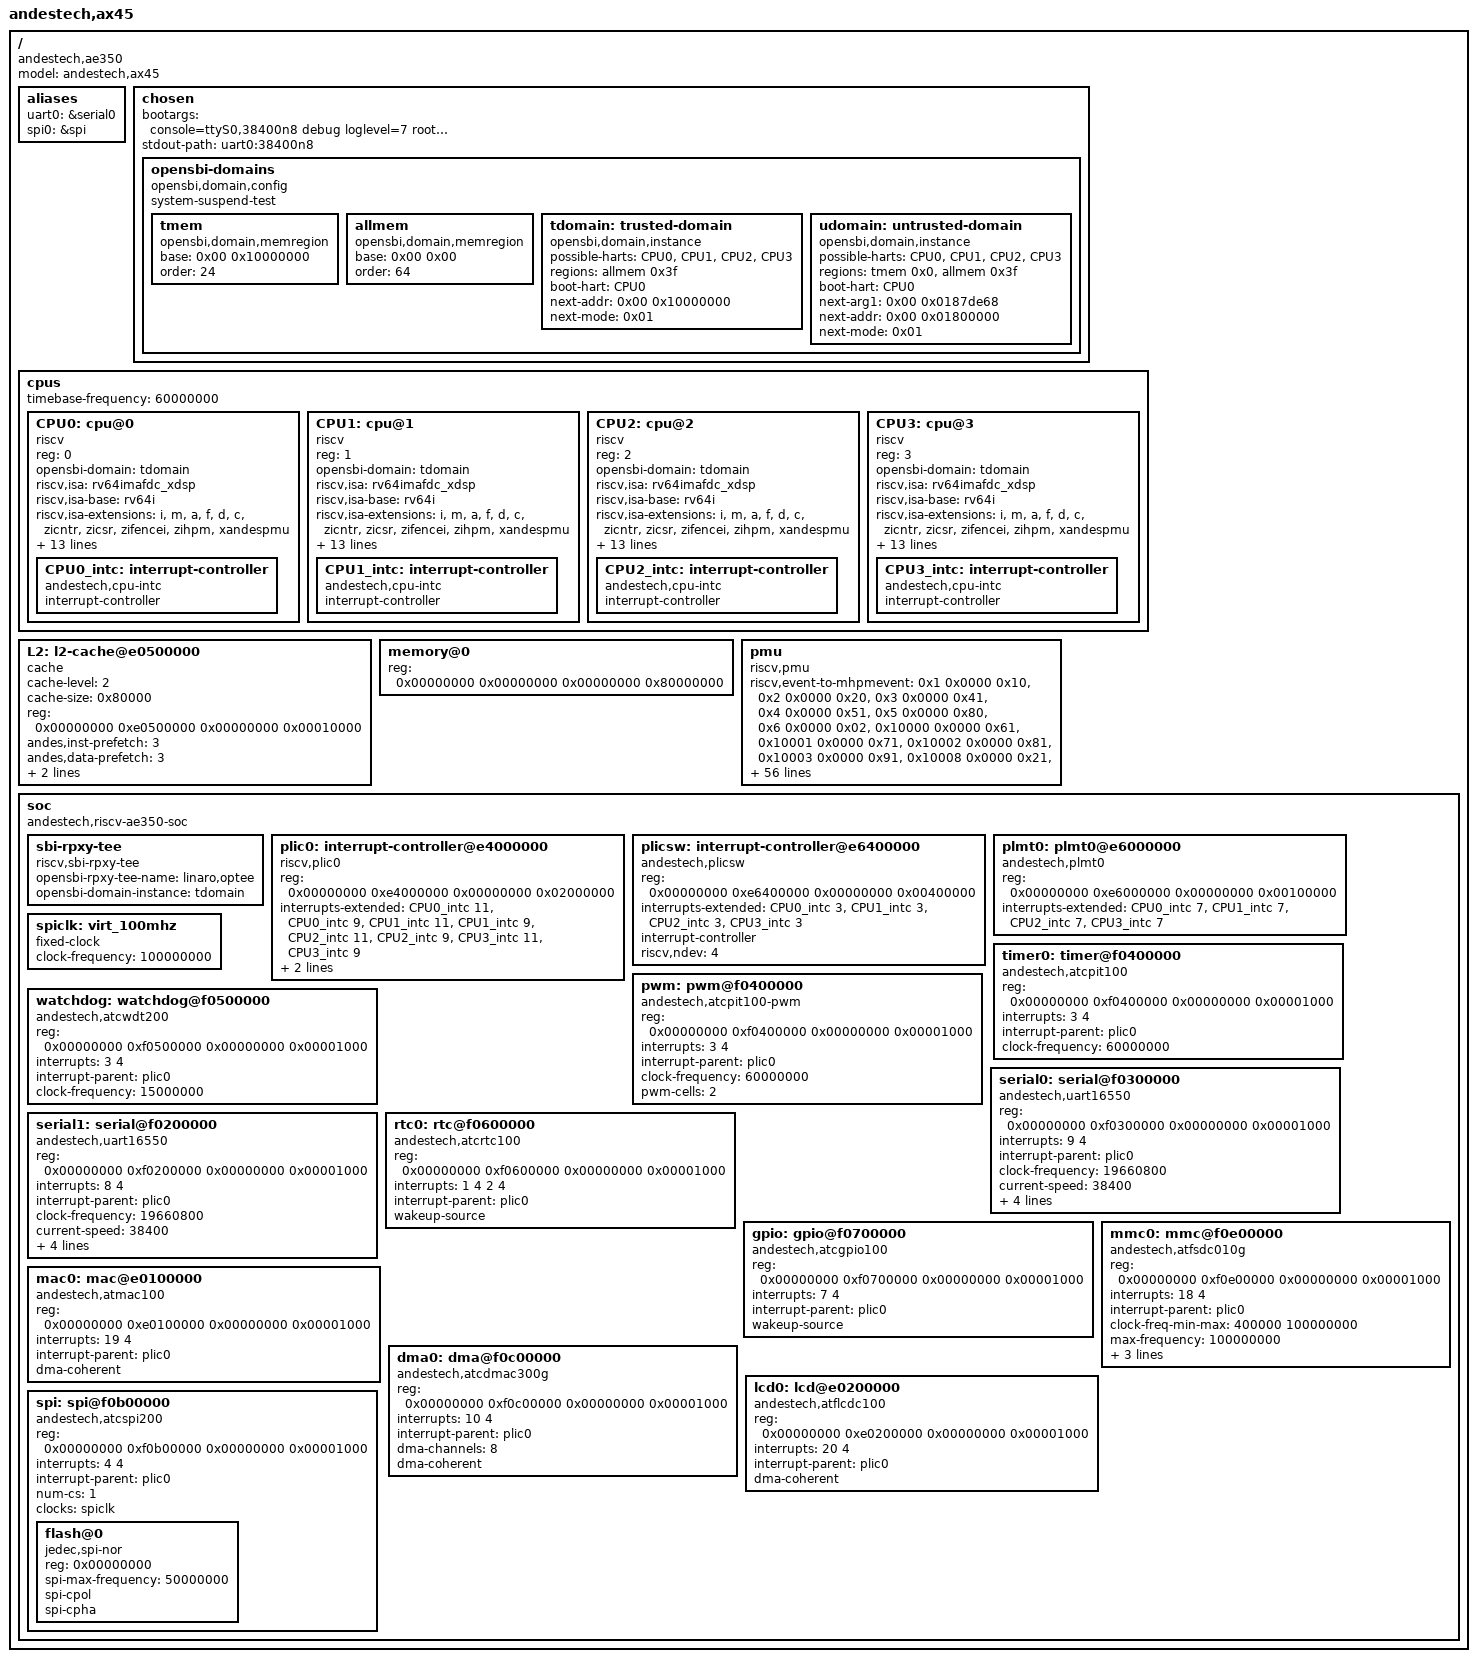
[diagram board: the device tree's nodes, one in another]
/dts-v1/;
/ {
	#address-cells = <2>;
	#size-cells = <2>;
	compatible = "andestech,ae350";
	model = "andestech,ax45";
	aliases {
		uart0 = &serial0;
		spi0 = &spi;
	};
	chosen {
		//bootargs = "earlycon=sbi console=ttyS0,38400n8 debug loglevel=7 rootwait root=/dev/mmcblk0p2 rw";
		bootargs = "console=ttyS0,38400n8 debug loglevel=7 rootwait root=/dev/mmcblk0p2 rw";
		stdout-path = "uart0:38400n8";
		opensbi-domains {
			compatible = "opensbi,domain,config";
			system-suspend-test;

			tmem: tmem {
				compatible = "opensbi,domain,memregion";
				base = <0x00 0x10000000>;
				order = <24>;
			};

			allmem: allmem {
				compatible = "opensbi,domain,memregion";
				base = <0x00 0x00>;
				order = <64>;
			};

			tdomain: trusted-domain {
				compatible = "opensbi,domain,instance";
				possible-harts = <&CPU0 &CPU1 &CPU2 &CPU3>;
				//   (E|SUX|SUW| SUR|MX|MW|MR)
				regions = <&allmem 0x3f>;
				boot-hart = <&CPU0>;
				//next-arg1 = <0x00 0x0187de58>; // dtb : FW_JUMP   : 0x02200000,
							       //       FW_DYNAMIC: use $a1 given by SPL
				next-addr = <0x00 0x10000000>; // tee.bin
				next-mode = <0x01>;
			};

			udomain: untrusted-domain {
				compatible = "opensbi,domain,instance";
				possible-harts = <&CPU0 &CPU1 &CPU2 &CPU3>;
				//   (E|SUX|SUW| SUR|MX|MW|MR)
				regions = <&tmem 0x0 &allmem 0x3f>;
				boot-hart = <&CPU0>;
				next-arg1 = <0x00 0x0187de68>; // dtb : FW_JUMP   : 0x2200000,
							       //       FW_DYNAMIC: 0x0187de58
				next-addr = <0x00 0x01800000>; // u-boot
				next-mode = <0x01>;
			};
		};
	};
	cpus {
		#address-cells = <1>;
		#size-cells = <0>;
		timebase-frequency = <60000000>;
		CPU0: cpu@0 {
			device_type = "cpu";
			reg = <0>;
			status = "okay";
			compatible = "riscv";
			opensbi-domain = <&tdomain>;
			riscv,isa = "rv64imafdc_xdsp";
			riscv,isa-base = "rv64i";
			riscv,isa-extensions = "i", "m", "a", "f", "d", "c", "zicntr", "zicsr",
					       "zifencei", "zihpm", "xandespmu";
			riscv,priv-major = <1>;
			riscv,priv-minor = <10>;
			mmu-type = "riscv,sv48";
			clock-frequency = <60000000>;
			i-cache-size = <0x8000>;
			i-cache-sets = <256>;
			i-cache-line-size = <64>;
			i-cache-block-size = <64>;
			d-cache-size = <0x8000>;
			d-cache-sets = <128>;
			d-cache-line-size = <64>;
			d-cache-block-size = <64>;
			next-level-cache = <&L2>;
			CPU0_intc: interrupt-controller {
				#interrupt-cells = <1>;
				interrupt-controller;
				compatible = "andestech,cpu-intc", "riscv,cpu-intc";
			};
		};
		CPU1: cpu@1 {
			device_type = "cpu";
			reg = <1>;
			status = "okay";
			compatible = "riscv";
			opensbi-domain = <&tdomain>;
			riscv,isa = "rv64imafdc_xdsp";
			riscv,isa-base = "rv64i";
			riscv,isa-extensions = "i", "m", "a", "f", "d", "c", "zicntr", "zicsr",
					       "zifencei", "zihpm", "xandespmu";
			riscv,priv-major = <1>;
			riscv,priv-minor = <10>;
			mmu-type = "riscv,sv48";
			clock-frequency = <60000000>;
			i-cache-size = <0x8000>;
			i-cache-sets = <256>;
			i-cache-line-size = <64>;
			i-cache-block-size = <64>;
			d-cache-size = <0x8000>;
			d-cache-sets = <128>;
			d-cache-line-size = <64>;
			d-cache-block-size = <64>;
			next-level-cache = <&L2>;
			CPU1_intc: interrupt-controller {
				#interrupt-cells = <1>;
				interrupt-controller;
				compatible = "andestech,cpu-intc", "riscv,cpu-intc";
			};
		};
		CPU2: cpu@2 {
			device_type = "cpu";
			reg = <2>;
			status = "okay";
			compatible = "riscv";
			opensbi-domain = <&tdomain>;
			riscv,isa = "rv64imafdc_xdsp";
			riscv,isa-base = "rv64i";
			riscv,isa-extensions = "i", "m", "a", "f", "d", "c", "zicntr", "zicsr",
					       "zifencei", "zihpm", "xandespmu";
			riscv,priv-major = <1>;
			riscv,priv-minor = <10>;
			mmu-type = "riscv,sv48";
			clock-frequency = <60000000>;
			i-cache-size = <0x8000>;
			i-cache-sets = <256>;
			i-cache-line-size = <64>;
			i-cache-block-size = <64>;
			d-cache-size = <0x8000>;
			d-cache-sets = <128>;
			d-cache-line-size = <64>;
			d-cache-block-size = <64>;
			next-level-cache = <&L2>;
			CPU2_intc: interrupt-controller {
				#interrupt-cells = <1>;
				interrupt-controller;
				compatible = "andestech,cpu-intc", "riscv,cpu-intc";
			};
		};
		CPU3: cpu@3 {
			device_type = "cpu";
			reg = <3>;
			status = "okay";
			compatible = "riscv";
			opensbi-domain = <&tdomain>;
			riscv,isa = "rv64imafdc_xdsp";
			riscv,isa-base = "rv64i";
			riscv,isa-extensions = "i", "m", "a", "f", "d", "c", "zicntr", "zicsr",
					       "zifencei", "zihpm", "xandespmu";
			riscv,priv-major = <1>;
			riscv,priv-minor = <10>;
			mmu-type = "riscv,sv48";
			clock-frequency = <60000000>;
			i-cache-size = <0x8000>;
			i-cache-sets = <256>;
			i-cache-line-size = <64>;
			i-cache-block-size = <64>;
			d-cache-size = <0x8000>;
			d-cache-sets = <128>;
			d-cache-line-size = <64>;
			d-cache-block-size = <64>;
			next-level-cache = <&L2>;
			CPU3_intc: interrupt-controller {
				#interrupt-cells = <1>;
				interrupt-controller;
				compatible = "andestech,cpu-intc", "riscv,cpu-intc";
			};
		};
	};
	L2: l2-cache@e0500000 {
		compatible = "cache";
		cache-level = <2>;
		cache-size = <0x80000>;
		reg = <0x00000000 0xe0500000 0x00000000 0x00010000>;
		andes,inst-prefetch = <3>;
		andes,data-prefetch = <3>;
		// The value format is <XRAMOCTL XRAMICTL>
		andes,tag-ram-ctl = <1 0>;
		andes,data-ram-ctl = <1 0>;
	};

	memory@0 {
		reg = <0x00000000 0x00000000 0x00000000 0x80000000>;
		device_type = "memory";
	};
	pmu: pmu {
		compatible 			= "riscv,pmu";
		riscv,event-to-mhpmevent =
						 <0x1 0x0000 0x10>, /* CPU_CYCLES          -> Cycle count */
						 <0x2 0x0000 0x20>, /* INSTRUCTIONS        -> Retired instruction count */
						 <0x3 0x0000 0x41>, /* CACHE_REFERENCES    -> D-Cache access */
						 <0x4 0x0000 0x51>, /* CACHE_MISSES        -> D-Cache miss */
						 <0x5 0x0000 0x80>, /* BRANCH_INSTRUCTIONS -> Conditional branch instruction count */
						 <0x6 0x0000 0x02>, /* BRANCH_MISSES       -> Misprediction of conditional branches */
						 <0x10000 0x0000 0x61>,  /* L1D_READ_ACCESS  -> D-Cache load access */
						 <0x10001 0x0000 0x71>,  /* L1D_READ_MISS    -> D-Cache load miss */
						 <0x10002 0x0000 0x81>,  /* L1D_WRITE_ACCESS -> D-Cache store access */
						 <0x10003 0x0000 0x91>,  /* L1D_WRITE_MISS   -> D-Cache store miss */
						 <0x10008 0x0000 0x21>,  /* L1I_READ_ACCESS  -> I-Cache access */
						 <0x10009 0x0000 0x31>;  /* L1I_READ_MISS    -> I-Cache miss */
		riscv,event-to-mhpmcounters = <0x1 0x6 0x78>,
					      <0x10000 0x10003 0x78>,
					      <0x10008 0x10009 0x78>;
		riscv,raw-event-to-mhpmcounters =
							<0x0 0x10 0xffffffff 0xffffffff 0x78>, /* Cycle count */
							<0x0 0x20 0xffffffff 0xffffffff 0x78>, /* Retired instruction count */
							<0x0 0x30 0xffffffff 0xffffffff 0x78>, /* Integer load instruction count */
							<0x0 0x40 0xffffffff 0xffffffff 0x78>, /* Integer store instruction count */
							<0x0 0x50 0xffffffff 0xffffffff 0x78>, /* Atomic instruction count */
							<0x0 0x60 0xffffffff 0xffffffff 0x78>, /* System instruction count */
							<0x0 0x70 0xffffffff 0xffffffff 0x78>, /* Integer computational instruction count */
							<0x0 0x80 0xffffffff 0xffffffff 0x78>, /* Conditional branch instruction count */
							<0x0 0x90 0xffffffff 0xffffffff 0x78>, /* Taken conditional branch instruction count */
							<0x0 0xA0 0xffffffff 0xffffffff 0x78>, /* JAL instruction count */
							<0x0 0xB0 0xffffffff 0xffffffff 0x78>, /* JALR instruction count */
							<0x0 0xC0 0xffffffff 0xffffffff 0x78>, /* Return instruction count */
							<0x0 0xD0 0xffffffff 0xffffffff 0x78>, /* Control transfer instruction count */
							<0x0 0xE0 0xffffffff 0xffffffff 0x78>, /* EXEC.IT instruction count */
							<0x0 0xF0 0xffffffff 0xffffffff 0x78>, /* Integer multiplication instruction count */
							<0x0 0x100 0xffffffff 0xffffffff 0x78>, /* Integer division instruction count */
							<0x0 0x110 0xffffffff 0xffffffff 0x78>, /* Floating-point load instruction count */
							<0x0 0x120 0xffffffff 0xffffffff 0x78>, /* Floating-point store instruction count */
							<0x0 0x130 0xffffffff 0xffffffff 0x78>, /* Floating-point addition/subtraction instruction count */
							<0x0 0x140 0xffffffff 0xffffffff 0x78>, /* Floating-point multiplication instruction count */
							<0x0 0x150 0xffffffff 0xffffffff 0x78>, /* Floating-point fused multiply-add instruction count */
							<0x0 0x160 0xffffffff 0xffffffff 0x78>, /* Floating-point division or square-root instruction count */
							<0x0 0x170 0xffffffff 0xffffffff 0x78>, /* Other floating-point instruction count */
							<0x0 0x180 0xffffffff 0xffffffff 0x78>, /* Integer multiplication and add/sub instruction count */
							<0x0 0x190 0xffffffff 0xffffffff 0x78>, /* Retired operation count */
							<0x0 0x01 0xffffffff 0xffffffff 0x78>, /* ILM access */
							<0x0 0x11 0xffffffff 0xffffffff 0x78>, /* DLM access */
							<0x0 0x21 0xffffffff 0xffffffff 0x78>, /* I-Cache access */
							<0x0 0x31 0xffffffff 0xffffffff 0x78>, /* I-Cache miss */
							<0x0 0x41 0xffffffff 0xffffffff 0x78>, /* D-Cache access */
							<0x0 0x51 0xffffffff 0xffffffff 0x78>, /* D-Cache miss */
							<0x0 0x61 0xffffffff 0xffffffff 0x78>, /* D-Cache load access */
							<0x0 0x71 0xffffffff 0xffffffff 0x78>, /* D-Cache load miss */
							<0x0 0x81 0xffffffff 0xffffffff 0x78>, /* D-Cache store access */
							<0x0 0x91 0xffffffff 0xffffffff 0x78>, /* D-Cache store miss */
							<0x0 0xA1 0xffffffff 0xffffffff 0x78>, /* D-Cache writeback */
							<0x0 0xB1 0xffffffff 0xffffffff 0x78>, /* Cycles waiting for I-Cache fill data */
							<0x0 0xC1 0xffffffff 0xffffffff 0x78>, /* Cycles waiting for D-Cache fill data */
							<0x0 0xD1 0xffffffff 0xffffffff 0x78>, /* Uncached fetch data access from bus */
							<0x0 0xE1 0xffffffff 0xffffffff 0x78>, /* Uncached load data access from bus */
							<0x0 0xF1 0xffffffff 0xffffffff 0x78>, /* Cycles waiting for uncached fetch data from bus */
							<0x0 0x101 0xffffffff 0xffffffff 0x78>, /* Cycles waiting for uncached load data from bus */
							<0x0 0x111 0xffffffff 0xffffffff 0x78>, /* Main ITLB access */
							<0x0 0x121 0xffffffff 0xffffffff 0x78>, /* Main ITLB miss */
							<0x0 0x131 0xffffffff 0xffffffff 0x78>, /* Main DTLB access */
							<0x0 0x141 0xffffffff 0xffffffff 0x78>, /* Main DTLB miss */
							<0x0 0x151 0xffffffff 0xffffffff 0x78>, /* Cycles waiting for Main ITLB fill data */
							<0x0 0x161 0xffffffff 0xffffffff 0x78>, /* Pipeline stall cycles caused by Main DTLB miss */
							<0x0 0x171 0xffffffff 0xffffffff 0x78>, /* Hardware prefetch bus access */
							<0x0 0x02 0xffffffff 0xffffffff 0x78>, /* Misprediction of conditional branches */
							<0x0 0x12 0xffffffff 0xffffffff 0x78>, /* Misprediction of taken conditional branches */
							<0x0 0x22 0xffffffff 0xffffffff 0x78>; /* Misprediction of targets of Return instructions */
	};
	soc {
		#address-cells = <2>;
		#size-cells = <2>;
		compatible = "andestech,riscv-ae350-soc", "simple-bus";
		ranges;
		sbi-rpxy-tee {
			opensbi-rpxy-tee-name = "linaro,optee";
			opensbi-domain-instance = <&tdomain>;
			compatible = "riscv,sbi-rpxy-tee";
		};
		plic0: interrupt-controller@e4000000 {
			compatible = "riscv,plic0";
			reg = <0x00000000 0xe4000000 0x00000000 0x02000000>;
			interrupts-extended = < &CPU0_intc 11 &CPU0_intc 9 &CPU1_intc 11 &CPU1_intc 9
						&CPU2_intc 11 &CPU2_intc 9 &CPU3_intc 11 &CPU3_intc 9>;
			interrupt-controller;
			#address-cells = <2>;
			#interrupt-cells = <2>;
			riscv,ndev = <71>;
		};
		plicsw: interrupt-controller@e6400000 {
			compatible = "andestech,plicsw";
			reg = <0x00000000 0xe6400000 0x00000000 0x00400000>;
			interrupts-extended = < &CPU0_intc 3 &CPU1_intc 3
						&CPU2_intc 3 &CPU3_intc 3>;
			interrupt-controller;
			#address-cells = <2>;
			#interrupt-cells = <2>;
			riscv,ndev = <4>;
		};
		plmt0: plmt0@e6000000 {
			compatible = "andestech,plmt0";
			reg = <0x00000000 0xe6000000 0x00000000 0x00100000>;
			interrupts-extended = < &CPU0_intc 7 &CPU1_intc 7
						&CPU2_intc 7 &CPU3_intc 7>;
		};
		spiclk: virt_100mhz {
			compatible = "fixed-clock";
			#clock-cells = <0>;
			clock-frequency = <100000000>;
		};
		timer0: timer@f0400000 {
			compatible = "andestech,atcpit100";
			reg = <0x00000000 0xf0400000 0x00000000 0x00001000>;
			interrupts = <3 4>;
			interrupt-parent = <&plic0>;
			clock-frequency = <60000000>;
		};
		pwm: pwm@f0400000 {
			compatible = "andestech,atcpit100-pwm";
			reg = <0x00000000 0xf0400000 0x00000000 0x00001000>;
			interrupts = <3 4>;
			interrupt-parent = <&plic0>;
			clock-frequency = <60000000>;
			pwm-cells = <2>;
		};
		watchdog: watchdog@f0500000 {
			compatible = "andestech,atcwdt200";
			reg = <0x00000000 0xf0500000 0x00000000 0x00001000>;
			interrupts = <3 4>;
			interrupt-parent = <&plic0>;
			clock-frequency = <15000000>;
		};
		serial0: serial@f0300000 {
			compatible = "andestech,uart16550", "ns16550a";
			reg = <0x00000000 0xf0300000 0x00000000 0x00001000>;
			interrupts = <9 4>;
			interrupt-parent = <&plic0>;
			clock-frequency = <19660800>;
			current-speed = <38400>;
			reg-shift = <2>;
			reg-offset = <32>;
			reg-io-width = <4>;
			no-loopback-test;
		};
serial1: serial@f0200000 {
	compatible = "andestech,uart16550", "ns16550a";
	reg = <0x00000000 0xf0200000 0x00000000 0x00001000>;
	interrupts = <8 4>;
	interrupt-parent = <&plic0>;
	clock-frequency = <19660800>;
	current-speed = <38400>;
	reg-shift = <2>;
	reg-offset = <32>;
	reg-io-width = <4>;
	no-loopback-test;
};
		rtc0: rtc@f0600000 {
			compatible = "andestech,atcrtc100";
			reg = <0x00000000 0xf0600000 0x00000000 0x00001000>;
			interrupts = <1 4 2 4>;
			interrupt-parent = <&plic0>;
			wakeup-source;
		};
		gpio: gpio@f0700000 {
			compatible = "andestech,atcgpio100";
			reg = <0x00000000 0xf0700000 0x00000000 0x00001000>;
			interrupts = <7 4>;
			interrupt-parent = <&plic0>;
			wakeup-source;
		};
		mac0: mac@e0100000 {
			compatible = "andestech,atmac100";
			reg = <0x00000000 0xe0100000 0x00000000 0x00001000>;
			interrupts = <19 4>;
			interrupt-parent = <&plic0>;
		dma-coherent;
		};
		mmc0: mmc@f0e00000 {
			compatible = "andestech,atfsdc010g";
			reg = <0x00000000 0xf0e00000 0x00000000 0x00001000>;
			interrupts = <18 4>;
			interrupt-parent = <&plic0>;
			clock-freq-min-max = <400000 100000000>;
			max-frequency = <100000000>;
			fifo-depth = <16>;
			dmas = <&dma0 9>;
			dma-names = "rxtx";
		dma-coherent;
		};
		dma0: dma@f0c00000 {
			compatible = "andestech,atcdmac300g";
			reg = <0x00000000 0xf0c00000 0x00000000 0x00001000>;
			interrupts = <10 4>;
			interrupt-parent = <&plic0>;
			dma-channels = <8>;
			#dma-cells = <1>;
			dma-coherent;
		};
		lcd0: lcd@e0200000 {
			compatible = "andestech,atflcdc100";
			reg = <0x00000000 0xe0200000 0x00000000 0x00001000>;
			interrupts = <20 4>;
			interrupt-parent = <&plic0>;
		dma-coherent;
		};
		spi: spi@f0b00000 {
			compatible = "andestech,atcspi200";
			reg = <0x00000000 0xf0b00000 0x00000000 0x00001000>;
			interrupts = <4 4>;
			interrupt-parent = <&plic0>;
			#address-cells = <1>;
			#size-cells = <0>;
			num-cs = <1>;
			clocks = <&spiclk>;
			flash@0 {
				compatible = "jedec,spi-nor";
				reg = <0x00000000>;
				spi-max-frequency = <50000000>;
				spi-cpol;
				spi-cpha;
			};
		};
	};
};

